# nrf54h20_enga_application register map
Vendor: Nordic Semiconductor; Series: nRF54h; File version: 1
CPU: CM33 r0p4, little endian, MPU, FPU, 3 interrupt priority bits, 480 interrupts, 4 SAU regions
Registers are 32-bit, read-write, reset 0x0 unless marked. A register's access mark holds for its fields unless they carry their own. Offsets are from the block's base; [hi:lo] are bit positions; lines under a group give offsets from that group; {n}, {i} and the like mark numbered series; 'fields as' and 'values as' point back to an identical list.

## GLOBAL_GPIOTE130_NS — GPIO Tasks and Events 0
Base 0x4F934000
Same registers: GLOBAL_GPIOTE130_S 0x5F934000
{0x0+4i} TASKS_OUT[{i}] (i=0..7) wo — Description collection: Task for writing to pin specified in CONFIG[n].PSEL. Action on pin is configured in CONFIG[n].POLARITY.
  [0] TASKS_OUT — Task for writing to pin specified in CONFIG[n].PSEL. Action on pin is configured in CONFIG[n].POLARITY.
    1=Trigger task
{0x30+4i} TASKS_SET[{i}] (i=0..7) wo — Description collection: Task for writing to pin specified in CONFIG[n].PSEL. Action on pin is to set it high.
  [0] TASKS_SET — Task for writing to pin specified in CONFIG[n].PSEL. Action on pin is to set it high.
    1=Trigger task
{0x60+4i} TASKS_CLR[{i}] (i=0..7) wo — Description collection: Task for writing to pin specified in CONFIG[n].PSEL. Action on pin is to set it low.
  [0] TASKS_CLR — Task for writing to pin specified in CONFIG[n].PSEL. Action on pin is to set it low.
    1=Trigger task
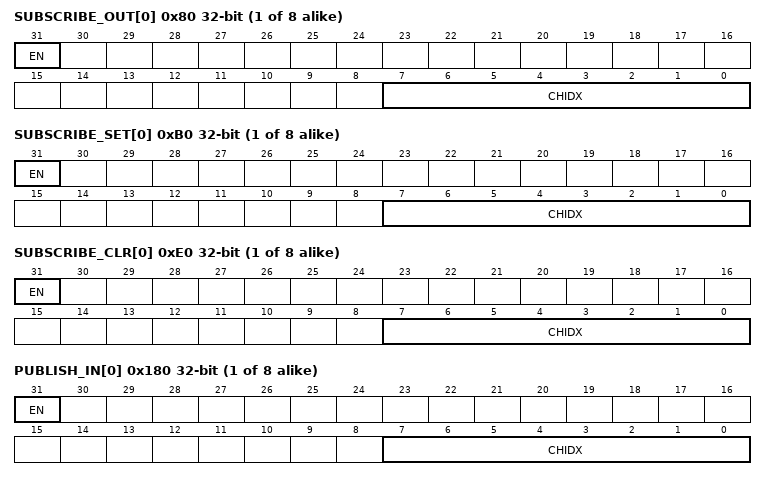
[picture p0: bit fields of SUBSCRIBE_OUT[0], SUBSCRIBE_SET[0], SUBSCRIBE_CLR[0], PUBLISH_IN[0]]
{0x80+4i} SUBSCRIBE_OUT[{i}] (i=0..7) — Description collection: Subscribe configuration for task OUT[n]
  [31] EN
    0=Disabled (Disable subscription); 1=Enabled (Enable subscription)
  [7:0] CHIDX — DPPI channel that task OUT[n] will subscribe to
{0xB0+4i} SUBSCRIBE_SET[{i}] (i=0..7) — Description collection: Subscribe configuration for task SET[n]
  [31] EN
    values as SUBSCRIBE_OUT[0].EN
  [7:0] CHIDX — DPPI channel that task SET[n] will subscribe to
{0xE0+4i} SUBSCRIBE_CLR[{i}] (i=0..7) — Description collection: Subscribe configuration for task CLR[n]
  [31] EN
    values as SUBSCRIBE_OUT[0].EN
  [7:0] CHIDX — DPPI channel that task CLR[n] will subscribe to
{0x100+4i} EVENTS_IN[{i}] (i=0..7) — Description collection: Event from pin specified in CONFIG[n].PSEL
  [0] EVENTS_IN — Event from pin specified in CONFIG[n].PSEL
    0=NotGenerated (Event not generated); 1=Generated (Event generated)
{0x140+8i} EVENTS_PORT[{i}] (i=0..3) group — Peripheral events.
  0x00 NONSECURE — Description cluster: Non-secure port event from owner n
    [0] NONSECURE — Non-secure port event from owner n
      values as EVENTS_IN[0].EVENTS_IN
  0x04 SECURE — Description cluster: Secure port event from owner n
    [0] SECURE — Secure port event from owner n
      values as EVENTS_IN[0].EVENTS_IN
{0x180+4i} PUBLISH_IN[{i}] (i=0..7) — Description collection: Publish configuration for event IN[n]
  [31] EN
    0=Disabled (Disable publishing); 1=Enabled (Enable publishing)
  [7:0] CHIDX — DPPI channel that event IN[n] will publish to
{0x1C0+8i} PUBLISH_PORT[{i}] (i=0..3) group — Publish configuration for events
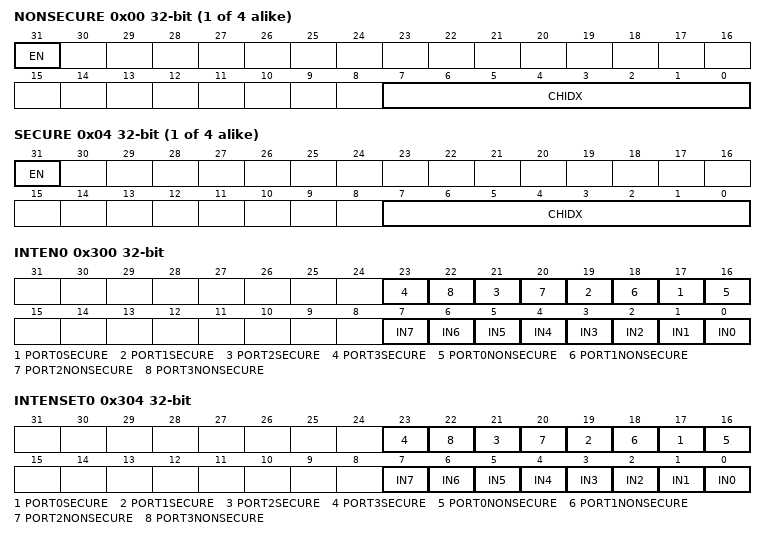
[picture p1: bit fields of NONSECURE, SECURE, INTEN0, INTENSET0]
  0x00 NONSECURE — Description cluster: Publish configuration for event PORT[n].NONSECURE
    [31] EN
      values as PUBLISH_IN[0].EN
    [7:0] CHIDX — DPPI channel that event PORT[n].NONSECURE will publish to
  0x04 SECURE — Description cluster: Publish configuration for event PORT[n].SECURE
    [31] EN
      values as PUBLISH_IN[0].EN
    [7:0] CHIDX — DPPI channel that event PORT[n].SECURE will publish to
0x300 INTEN0 — Enable or disable interrupt
  [all] fields
    0=Disabled; 1=Enabled
  [2n+17] PORT{n}SECURE (n=0..3) — Enable or disable interrupt for event PORT{n}SECURE
  [2n+16] PORT{n}NONSECURE (n=0..3) — Enable or disable interrupt for event PORT{n}NONSECURE
  [n] IN{n} (n=0..7) — Enable or disable interrupt for event IN[{n}]
0x304 INTENSET0 — Enable interrupt
  [all] fields
    on read: 0=Disabled (Read: Disabled); 1=Enabled (Read: Enabled) | on write: 1=Set (Enable)
  [2n+17] PORT{n}SECURE (n=0..3) — Write '1' to enable interrupt for event PORT{n}SECURE
  [2n+16] PORT{n}NONSECURE (n=0..3) — Write '1' to enable interrupt for event PORT{n}NONSECURE
  [n] IN{n} (n=0..7) — Write '1' to enable interrupt for event IN[{n}]
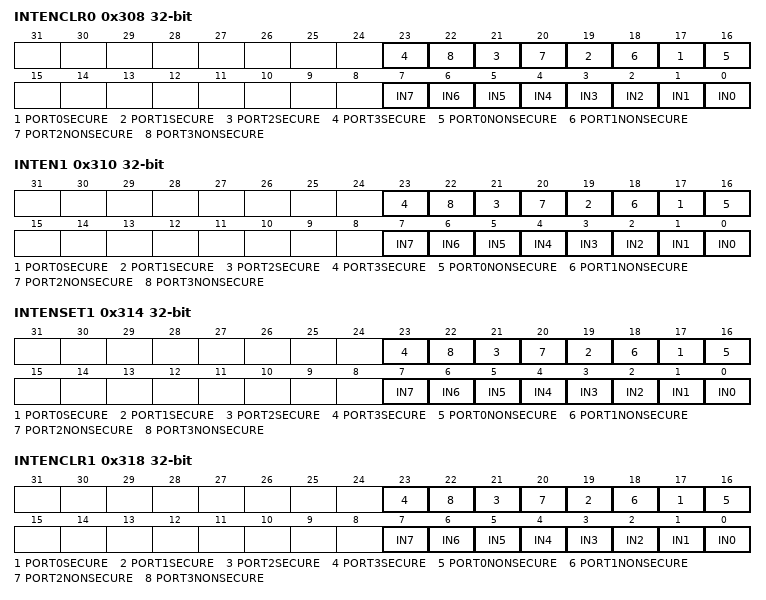
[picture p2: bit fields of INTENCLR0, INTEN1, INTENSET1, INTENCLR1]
0x308 INTENCLR0 — Disable interrupt
  [all] fields
    on read: 0=Disabled (Read: Disabled); 1=Enabled (Read: Enabled) | on write: 1=Clear (Disable)
  [2n+17] PORT{n}SECURE (n=0..3) — Write '1' to disable interrupt for event PORT{n}SECURE
  [2n+16] PORT{n}NONSECURE (n=0..3) — Write '1' to disable interrupt for event PORT{n}NONSECURE
  [n] IN{n} (n=0..7) — Write '1' to disable interrupt for event IN[{n}]
0x310 INTEN1 — Enable or disable interrupt
  fields as INTEN0
0x314 INTENSET1 — Enable interrupt
  fields as INTENSET0
0x318 INTENCLR1 — Disable interrupt
  fields as INTENCLR0
0x504 LATENCY reset 0x1 — Latency selection for Event mode (MODE=Event) with rising or falling edge detection on the pin.
  [0] LATENCY — Latency setting
    0=Low power setting, for signals with minimum hold time tGPIOTE,HOLD,LP; refer to Electrical specification section; 1=Low latency setting, for signals with minimum hold time tGPIOTE,HOLD,LL; refer to Electrical specification section
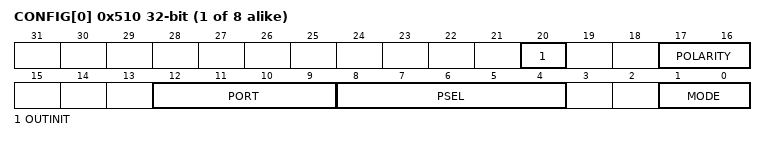
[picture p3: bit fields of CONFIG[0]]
{0x510+4i} CONFIG[{i}] (i=0..7) — Description collection: Configuration for OUT[n], SET[n], and CLR[n] tasks and IN[n] event
  [20] OUTINIT — When in task mode: Initial value of the output when the GPIOTE channel is configured. When in event mode: No effect.
    0=Low (Task mode: Initial value of pin before task triggering is low); 1=High (Task mode: Initial value of pin before task triggering is high)
  [17:16] POLARITY — When In task mode: Operation to be performed on output when OUT[n] task is triggered. When In event mode: Operation on input that shall trigger IN[n] event.
    0=None (Task mode: No effect on pin from OUT[n] task. Event mode: no IN[n] event generated on pin activity.); 1=LoToHi (Task mode: Set pin from OUT[n] task. Event mode: Generate IN[n] event when rising edge on pin.); 2=HiToLo (Task mode: Clear pin from OUT[n] task. Event mode: Generate IN[n] event when falling edge on pin.); 3=Toggle (Task mode: Toggle pin from OUT[n]. Event mode: Generate IN[n] when any change on pin.)
  [12:9] PORT — Port number
  [8:4] PSEL — GPIO number associated with SET[n], CLR[n], and OUT[n] tasks and IN[n] event
  [1:0] MODE
    0=Disabled. Pin specified by PSEL will not be acquired by the GPIOTE module.; 1=Event mode; 3=Task mode
{0x600+4i} DEBOUNCE[{i}] (i=0..7) — Description collection: Debounce mode for GPIOTE channel n
  [0] MODE
    0=Mode 0: Low power, non-constant latency debounce method (as in nRF52); 1=Mode 1: High power, constant latency debounce method (as in nRF51)
